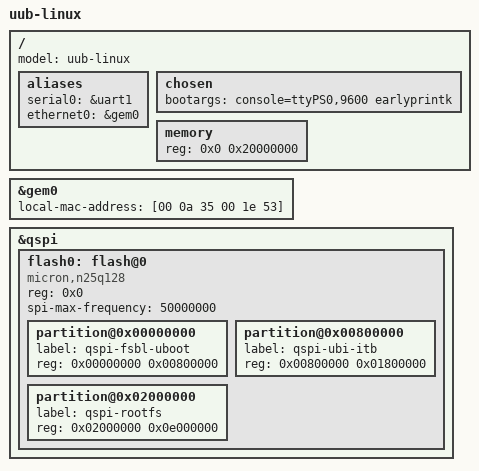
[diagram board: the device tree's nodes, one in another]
/*
 * CAUTION: This file is automatically generated by PetaLinux SDK.
 * DO NOT modify this file
 */

/include/ "skeleton.dtsi"
/include/ "zynq-7000.dtsi"
/include/ "pcw.dtsi"

/ {
	model = "uub-linux";
	aliases {
		serial0 = &uart1;
		ethernet0 = &gem0;
	};
	chosen {
		bootargs = "console=ttyPS0,9600 earlyprintk";
	};
	memory {
		device_type = "memory";
		reg = <0x0 0x20000000>;
	};
};

&gem0 {
	local-mac-address = [00 0a 35 00 1e 53];
};

&qspi {
	#address-cells = <1>;
	#size-cells = <0>;
	flash0: flash@0 {
		compatible = "micron,n25q128";
		reg = <0x0>;
		#address-cells = <1>;
		#size-cells = <1>;
		spi-max-frequency = <50000000>;
		partition@0x00000000 {
			label = "qspi-fsbl-uboot";
			reg = <0x00000000 0x00800000>;
		};
		partition@0x00800000 {
			label = "qspi-ubi-itb";
			reg = <0x00800000 0x01800000>;
		};
		partition@0x02000000 {
			label = "qspi-rootfs";
			reg = <0x02000000 0x0e000000>;
		};
	};
};

